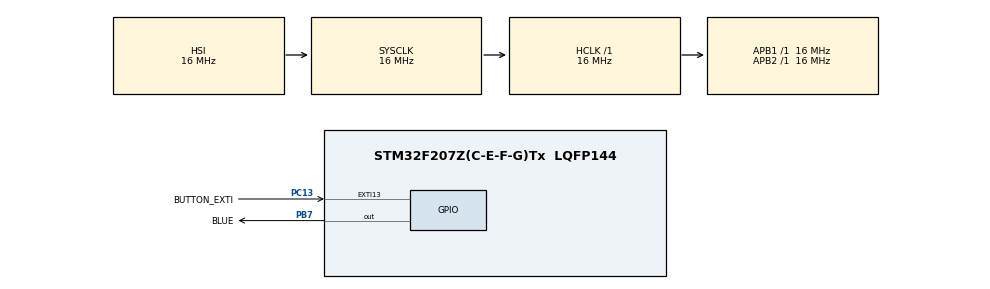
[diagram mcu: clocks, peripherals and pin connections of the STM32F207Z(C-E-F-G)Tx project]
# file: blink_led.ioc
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Mcu.Family=STM32F2
Mcu.Name=STM32F207Z(C-E-F-G)Tx
Mcu.Package=LQFP144
NVIC.EXTI15_10_IRQn=true\:0\:0\:false\:false\:true\:true\:true\:true
NVIC.PriorityGroup=NVIC_PRIORITYGROUP_4
PB7.GPIO_Label=BLUE
PB7.Signal=GPIO_Output
PC13.GPIO_Label=BUTTON_EXTI
PC13.Signal=GPXTI13
ProjectManager.HeapSize=0x200
ProjectManager.StackSize=0x400
ProjectManager.TargetToolchain=STM32CubeIDE
RCC.48MHZClocksFreq_Value=48000000
RCC.AHBFreq_Value=16000000
RCC.APB1Freq_Value=16000000
RCC.APB2Freq_Value=16000000
RCC.CortexFreq_Value=16000000
RCC.HSE_VALUE=25000000
RCC.HSI_VALUE=16000000
RCC.LSE_VALUE=32768
RCC.SYSCLKFreq_VALUE=16000000
RCC.VCOOutputFreq_Value=192000000
board=custom

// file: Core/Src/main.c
/* USER CODE BEGIN Header */
/**
  ******************************************************************************
  * @file           : main.c
  * @brief          : Main program body
  ******************************************************************************
  * @attention
  *
  * Copyright (c) 2024 STMicroelectronics.
  * All rights reserved.
  *
  * This software is licensed under terms that can be found in the LICENSE file
  * in the root directory of this software component.
  * If no LICENSE file comes with this software, it is provided AS-IS.
  *
  ******************************************************************************
  */
/* USER CODE END Header */
#include "main.h"

void SystemClock_Config(void);
static void MX_GPIO_Init(void);

int main(void)
{

  /* MCU Configuration--------------------------------------------------------*/

  /* Reset of all peripherals, Initializes the Flash interface and the Systick. */
  HAL_Init();

  /* Configure the system clock */
  SystemClock_Config();

  /* Initialize all configured peripherals */
  MX_GPIO_Init();

  /* Infinite loop */
  while (1)
  {

  }
}

void SystemClock_Config(void)
{
  RCC_OscInitTypeDef RCC_OscInitStruct = {0};
  RCC_ClkInitTypeDef RCC_ClkInitStruct = {0};

  /** Initializes the RCC Oscillators according to the specified parameters
  * in the RCC_OscInitTypeDef structure.
  */
  RCC_OscInitStruct.OscillatorType = RCC_OSCILLATORTYPE_HSI;
  RCC_OscInitStruct.HSIState = RCC_HSI_ON;
  RCC_OscInitStruct.HSICalibrationValue = RCC_HSICALIBRATION_DEFAULT;
  RCC_OscInitStruct.PLL.PLLState = RCC_PLL_NONE;
  if (HAL_RCC_OscConfig(&RCC_OscInitStruct) != HAL_OK)
  {
    Error_Handler();
  }

  /** Initializes the CPU, AHB and APB buses clocks
  */
  RCC_ClkInitStruct.ClockType = RCC_CLOCKTYPE_HCLK|RCC_CLOCKTYPE_SYSCLK
                              |RCC_CLOCKTYPE_PCLK1|RCC_CLOCKTYPE_PCLK2;
  RCC_ClkInitStruct.SYSCLKSource = RCC_SYSCLKSOURCE_HSI;
  RCC_ClkInitStruct.AHBCLKDivider = RCC_SYSCLK_DIV1;
  RCC_ClkInitStruct.APB1CLKDivider = RCC_HCLK_DIV1;
  RCC_ClkInitStruct.APB2CLKDivider = RCC_HCLK_DIV1;

  if (HAL_RCC_ClockConfig(&RCC_ClkInitStruct, FLASH_LATENCY_0) != HAL_OK)
  {
    Error_Handler();
  }
}

static void MX_GPIO_Init(void)
{
  GPIO_InitTypeDef GPIO_InitStruct = {0};

  /* GPIO Ports Clock Enable */
  __HAL_RCC_GPIOC_CLK_ENABLE();
  __HAL_RCC_GPIOB_CLK_ENABLE();

  /*Configure GPIO pin Output Level */
  HAL_GPIO_WritePin(BLUE_GPIO_Port, BLUE_Pin, GPIO_PIN_RESET);

  /*Configure GPIO pin : BUTTON_EXTI_Pin */
  GPIO_InitStruct.Pin = BUTTON_EXTI_Pin;
  GPIO_InitStruct.Mode = GPIO_MODE_IT_RISING;
  GPIO_InitStruct.Pull = GPIO_NOPULL;
  HAL_GPIO_Init(BUTTON_EXTI_GPIO_Port, &GPIO_InitStruct);

  /*Configure GPIO pin : BLUE_Pin */
  GPIO_InitStruct.Pin = BLUE_Pin;
  GPIO_InitStruct.Mode = GPIO_MODE_OUTPUT_PP;
  GPIO_InitStruct.Pull = GPIO_NOPULL;
  GPIO_InitStruct.Speed = GPIO_SPEED_FREQ_LOW;
  HAL_GPIO_Init(BLUE_GPIO_Port, &GPIO_InitStruct);

  /* EXTI interrupt init*/
  HAL_NVIC_SetPriority(EXTI15_10_IRQn, 0, 0);
  HAL_NVIC_EnableIRQ(EXTI15_10_IRQn);

}

/* USER CODE BEGIN 4 */
void HAL_GPIO_EXTI_Callback(uint16_t GPIO_Pin)
{
    if(GPIO_Pin == BUTTON_EXTI_Pin) {
        HAL_GPIO_TogglePin(BLUE_GPIO_Port, BLUE_Pin);
    } else {
        __NOP();
    }
}
/* USER CODE END 4 */

void Error_Handler(void)
{
  __disable_irq();
  while (1)
  {
  }
}
